# a34g43x register map
Vendor: ABOV Semiconductor Co., Ltd.; File version: 1.0
CPU: CM4 r0p1, little endian, MPU, FPU, VTOR, 4 interrupt priority bits
Registers are 32-bit, read-write, reset 0x0 unless marked. A register's access mark holds for its fields unless they carry their own. Offsets are from the block's base; [hi:lo] are bit positions; {n}, {i} and the like mark numbered series.

## DMA — Direct Memory Access Control
Base 0x50000400
Same registers: DMA{n} {0x40000400+0x10*n} (n=0..15)
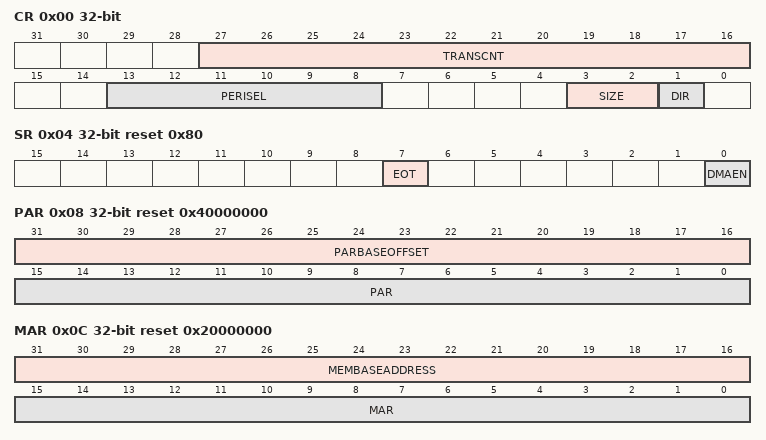
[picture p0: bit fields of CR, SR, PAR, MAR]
0x00 CR — DMA Control Register
  [27:16] TRANSCNT — DMA Transmit counter
  [13:8] PERISEL — Peripheral Selection Bit
  [3:2] SIZE — Bus Transmit Size
    0=Byte (transmit byte size); 1=half_word (transmit half word size); 2=word (transmit word size)
  [1] DIR — Transmit direction selection bit
    0=MEM-PERI (Memory->Peripheral); 1=PERI-MEM (Peripheral->Memory)
0x04 SR reset 0x80 — DMA Status Register
  [7] EOT ro — Transmit is over
  [0] DMAEN — DMA Enable Bit
0x08 PAR reset 0x40000000 — DMA Peripheral address register
  [31:16] PARBASEOFFSET — Peripheral Base Offset
  [15:0] PAR — Peripheral address bit
0x0C MAR reset 0x20000000 — DMA Memory address register
  [31:16] MEMBASEADDRESS — Memory Base Address
  [15:0] MAR — Purpose Memory Address

## WDT — WATCH-DOG TIMER
Base 0x40000200
0x00 LR — Watch-dog Timer Load Register
  [31:0] LR — WDT Load Value Bits
0x04 CNT reset 0x7A12 — Watch-dog Timer Counter Register
  [31:0] CNT ro — Watch-dog Timer Counter Value Bits
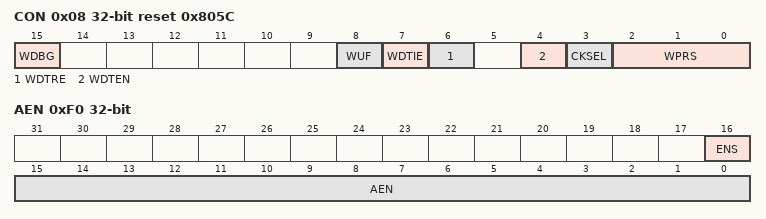
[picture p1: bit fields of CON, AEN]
0x08 CON reset 0x805C — Watch-dog Timer Control Register
  [15] WDBG — Watch-dog Timer Control in debugging mode
  [8] WUF — Watch-dog Timer Underflow Flag Bit, when write WDTLR register, this bit is cleared.
  [7] WDTIE — Watch-dog Timer Underflow Interrupt Enable bit
  [6] WDTRE — Watch-dog Timer Underflow Reset Enable bit
  [4] WDTEN — Watch-dog Timer Counter Enable bit
  [3] CKSEL — Watch-dog Timer Clock Source Selection Bit
  [2:0] WPRS — Watch-dog Timer Counter Clock Prescaler bit
    0=WDTCLKIN_DIV_BY_1 (WDT Input Clock divide by 1); 1=WDTCLKIN_DIV_BY_4 (WDT Input Clock divide by 4); 2=WDTCLKIN_DIV_BY_8 (WDT Input Clock divide by 8); 3=WDTCLKIN_DIV_BY_16 (WDT Input Clock divide by 16); 4=WDTCLKIN_DIV_BY_32 (WDT Input Clock divide by 32); 5=WDTCLKIN_DIV_BY_64 (WDT Input Clock divide by 64); 6=WDTCLKIN_DIV_BY_128 (WDT Input Clock divide by 128); 7=WDTCLKIN_DIV_BY_256 (WDT Input Clock divide by 256)
0xF0 AEN — Watch-dog Timer Master Lock/Reload Register
  [16] ENS ro — Enable status bit
  [15:0] AEN — WDT Master Lock Enable Register (Access = 0xA55A, Reload = 0x555A)

## PWM — PWM Generator
Base 0x50002000
Same registers: PWM0 0x40002000, PWM1 0x40002020, PWM2 0x40002040, PWM3 0x40002060, PWM4 0x40002080, PWM5 0x40002100, PWM6 0x40002120, PWM7 0x40002140, PWM8 0x40002160, PWM9 0x40002180
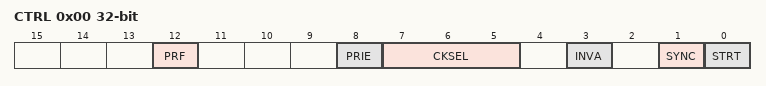
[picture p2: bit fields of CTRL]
0x00 CTRL — PWM n Control Register
  [12] PRF — Periodic interrupt occurs (write 1 to clear)
  [8] PRIE — Enable periodic interrupt
  [7:5] CKSEL — input clock divided
  [3] INVA — Inverted output
  [1] SYNC — Synchronize this channel to the other channels
  [0] STRT — startPWM counter
0x04 CNT — PWM n Counter Register
  [15:0] CNT — Current counter value
0x08 PER — PWM n Counter Period Register
  [15:0] PERIOD — PWM period value
0x0C COMP — PWM n Compare Register
  [15:0] COMP — Comparator value

## PWMPRS
Base 0x500020A0
Same registers: PWMPRS0 0x400020A0, PWMPRS1 0x400021A0
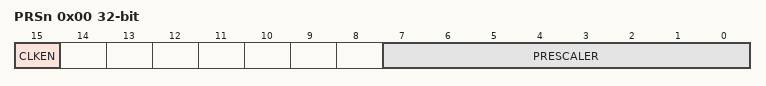
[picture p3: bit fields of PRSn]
0x00 PRSn — PWM Prescaler Register n
  [15] CLKEN — Stop/Run prescaler n clock
  [7:0] PRESCALER — Prescaler value of unit n

## TIMER — TIMER COUNTER
Base 0x50003000
Same registers: TIMER{n} {0x40003000+0x40*n} (n=0..9)
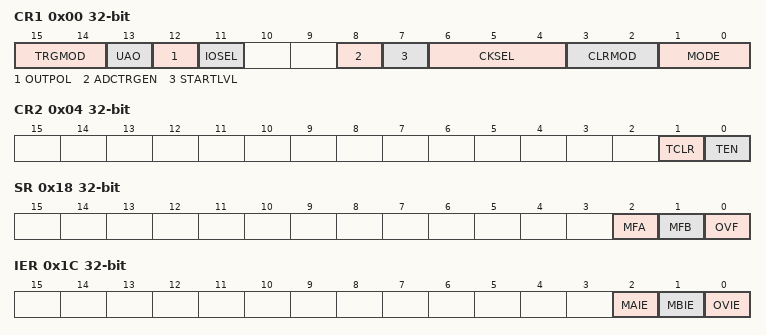
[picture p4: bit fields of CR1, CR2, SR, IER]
0x00 CR1 — Timer Control Register1
  [15:14] TRGMOD — Timer ADC Trigger Mode Selection Bit
    0=GRA (GRA Value Trigger Mode (Normal Mode)); 2=TRGPNT (TRGPNT Value Trigger Mode); 3=GRA_TRGPNT (GRA, TRGPNT Value Both Trigger Mode)
  [13] UAO — GRA, GRB Update Mode Selection bit
    0=Next_Period (Write Value Apply to next period); 1=Current_Period (Write value apply to current period)
  [12] OUTPOL — TIMER Output Polarity Selection Bit
    0=Normal Output; 1=Polarity (Polairty Output)
  [11] IOSEL — TIMER Input/Output Selection Bit
    0=Input (Timer Input Port Setting); 1=Output (Timer Output Port Setting)
  [8] ADCTRGEN — ADC Trigger Source Enable Bit
    0=No_Used; 1=Used
  [7] STARTLVL — Interval/PWM/One-shot Mode Initial output value setting
    0=Low (Output Start Low); 1=High (Output Start High)
  [6:4] CKSEL — Timer Clock Source Selection bit
    0=PCLK/2 (Counter Clock is PCLK/2); 1=PCLK/4 (Counter Clock is PCLK/4); 2=PCLK/16 (Counter Clock is PCLK/16); 3=PCLK/64 (Counter Clock is PCLK/64); 4=EXT0(MCCR3) (Counter Clock is EXT0(MCCR3)); 6=TnC (Counter Clock is TnC (input pin))
  [3:2] CLRMOD — Capture Mode Clear Selection bit
    0=Rising Edge Clear Mode; 1=Falling Edge Clear Mode; 2=Both (Rising/Falling Edge Clear Mode); 3=Not Clear Mode
  [1:0] MODE — TIMER Operating Mode Control Bit
    0=Interval (Timer is Interval Mode); 1=PWM (Timer is PWM Mode); 2=One-shot (Timer is One-Shot Mode); 3=Capture (Timer is Capture Mode)
0x04 CR2 — Timer Control Register2
  [1] TCLR wo — Timer Counter Register Clear Bit
  [0] TEN — Timer Counter
    0=Disable (Timer Disable); 1=Enable (Timer Enable)
0x08 PRS — Timer Prescaler Register
  [9:0] PRS — Counter Clock Prescaler Value, TCLK=CLOCK_IN/(PRS+1)
0x0C GRA — Timer General Data Register A
  [15:0] GRA — GRA Value Bit
0x10 GRB — Timer General Data Register B
  [15:0] GRB — GRB Balue Bit
0x14 CNT — Timer Counter Register
  [15:0] CNT — Timer Counter bits.
0x18 SR — Timer Status Register
  [2] MFA — GRA Match Flag
  [1] MFB — GRB Match Flag
  [0] OVF — Counter Overflow Flag
0x1C IER — Timer Interrupt Enable Register
  [2] MAIE — GRA Match Interrupt Enable bit
  [1] MBIE — GRB Match Interrupt Enable bit
  [0] OVIE — Counter Overflow Interrupt Enable bit
0x20 TRGPNT — Timer Trigger Point Register
  [15:0] TRGPNT — Timer Trigger Point Value Bit
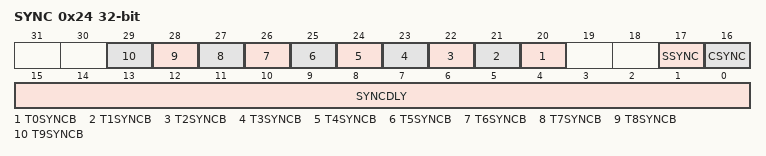
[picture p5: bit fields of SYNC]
0x24 SYNC — Timer Sync Setting Register
  [n+20] T{n}SYNCB (n=0..9) — Timer {n} sync enable bit
    0=Disable (SYNC Disable); 1=Enable (SYNC Enable)
  [17] SSYNC — Timer n Counter Start Sync
    0=Disable (SYNC Disable); 1=Enable (SYNC Enable)
  [16] CSYNC — Timer n Counter Clear Sync
    0=Disable (SYNC Disable); 1=Enable (SYNC Enable)
  [15:0] SYNCDLY — SYNC Delay Counter Value Setting Bit
